# PWMSS register map
Vendor: Texas Instruments
Peripheral module from a debugger description file (folder am437x).
Registers are 32-bit, read-only, no defined reset value unless marked. A register's access mark holds for its fields unless they carry their own. Offsets are as the file gives them; lines under a group give offsets from that group; [hi:lo] are bit positions; {n}, {i} and the like mark numbered series; 'fields as' and 'values as' point back to an identical list; <NAME> marks a mode.

## PWMSS
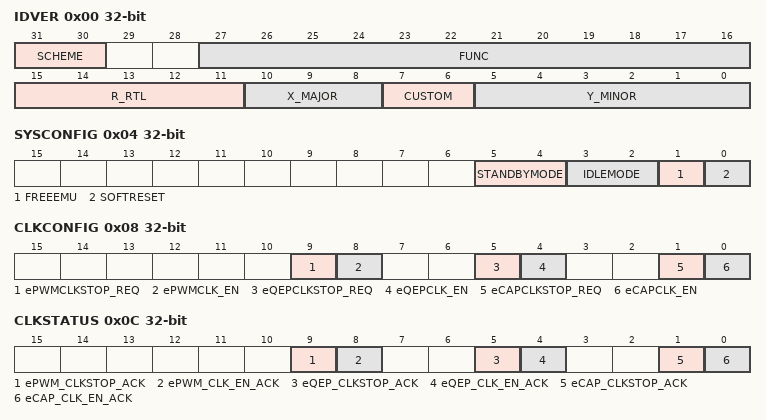
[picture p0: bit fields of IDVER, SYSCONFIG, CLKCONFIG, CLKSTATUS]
0x00 IDVER — The IP revision register is used by software to track features, bugs, and compatibility.
  [31:30] SCHEME — Used to distinguish between the old scheme and current.
  [27:16] FUNC
  [15:11] R_RTL — RTL version (R), maintained by IP design owner.
  [10:8] X_MAJOR — Major revision (X)
  [7:6] CUSTOM
  [5:0] Y_MINOR — Minor revision (Y)
0x04 SYSCONFIG access per field — The system configuration register is used for clock management configuration.
  [5:4] STANDBYMODE rw — Configuration of the local initiator state management mode. [[br]] By definition, initiator may generate read/write transaction as long as it is out of STANDBY state.
    3=en_4_0x3 (Reserved.); 2=en_3_0x2 (Smart-standby mode: local initiator standby status depends on local conditions, i.e., the module's functional requirement from the initiator. IP module should not generate (initiator-related) wakeup events.); 1=en_2_0x1 (No-standby mode: local initiator is unconditionally placed out of standby state. Backup mode, for debug only.); 0=en_1_0x0 (Force-standby mode: local initiator is unconditionally placed in standby state. Backup mode, for debug only.)
  [3:2] IDLEMODE rw — Configuration of the local target state management mode. [[br]] By definition, target can handle read/write transaction as long as it is out of IDLE state.
    3=en_4_0x3 (Reserved.); 2=en_3_0x2 (Smart-idle mode: local target's idle state eventually follows (acknowledges) the system's idle requests, depending on the IP module's internal requirements. IP module shall not generate (IRQ- or DMA-request-related) wakeup events.); 1=en_2_0x1 (No-idle mode: local target never enters idle state. Backup mode, for debug only.); 0=en_1_0x0 (Force-idle mode: local target's idle state follows (acknowledges) the system's idle requests unconditionally, i.e. regardless of the IP module's internal requirements. Backup mode, for debug only.)
  [1] FREEEMU rw — Sensitivity to emulation (debug) suspend event from Debug Subsystem.
    1=en_2_0x1 (IP module is not sensitive to emulation suspend event. Debug suspend event is ignored.); 0=en_1_0x0 (IP module is sensitive to emulation suspend.)
  [0] SOFTRESET rw — Software reset (optional)
0x08 CLKCONFIG access per field — The clock configuration register is used in the PWMSS submodule for clkstop req and clk_en control.
  [9] ePWMCLKSTOP_REQ rw — This bit controls the clkstop_req input to the ePWM module.
  [8] ePWMCLK_EN rw — This bit controls the clk_en input to the ePWM module.
  [5] eQEPCLKSTOP_REQ rw — This bit controls the clkstop_req input to the eQEP module
  [4] eQEPCLK_EN rw — This bit controls the clk_en input to the eQEP module.
  [1] eCAPCLKSTOP_REQ rw — This bit controls the clkstop_req input to the eCAP module.
  [0] eCAPCLK_EN rw — This bit controls the clk_en input to the eCAP module.
0x0C CLKSTATUS — The clock status register is used in the PWMSS submodule for clkstop ack and clk_en ack status.
  [9] ePWM_CLKSTOP_ACK — This bit is the clkstop_req_ack status output of the ePWM module.
  [8] ePWM_CLK_EN_ACK — This bit is the clk_en status output of the ePWM module.
  [5] eQEP_CLKSTOP_ACK — This bit is the clkstop_req_ack status output of the eQEP module.
  [4] eQEP_CLK_EN_ACK — This bit is the clk_en status output of the eQEP module.
  [1] eCAP_CLKSTOP_ACK — This bit is the clkstop_req_ack status output of the eCAP module.
  [0] eCAP_CLK_EN_ACK — This bit is the clk_en status output of the eCAP module.
